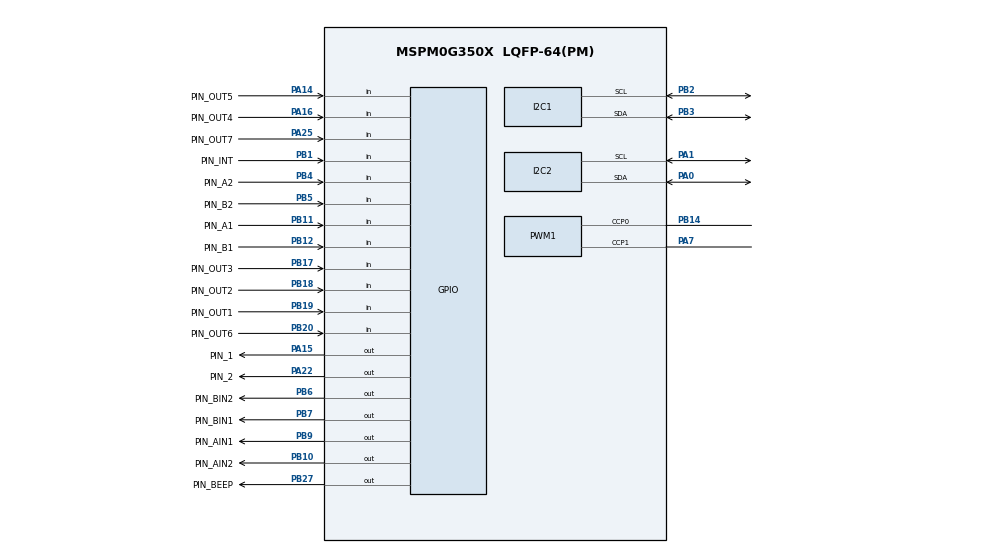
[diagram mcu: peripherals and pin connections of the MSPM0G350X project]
/**
 * @cliArgs --device "MSPM0G350X" --part "Default" --package "LQFP-64(PM)" --product "mspm0_sdk@2.05.00.05"
 * @versions {"tool":"1.24.0+4110"}
 */

/**
 * Import the modules used in this configuration.
 */
const GPIO   = scripting.addModule("/ti/driverlib/GPIO", {}, false);
const GPIO1  = GPIO.addInstance();
const GPIO2  = GPIO.addInstance();
const GPIO3  = GPIO.addInstance();
const GPIO4  = GPIO.addInstance();
const GPIO5  = GPIO.addInstance();
const I2C    = scripting.addModule("/ti/driverlib/I2C", {}, false);
const I2C1   = I2C.addInstance();
const I2C2   = I2C.addInstance();
const PWM    = scripting.addModule("/ti/driverlib/PWM", {}, false);
const PWM1   = PWM.addInstance();
const SYSCTL = scripting.addModule("/ti/driverlib/SYSCTL");
const TIMER  = scripting.addModule("/ti/driverlib/TIMER", {}, false);
const TIMER1 = TIMER.addInstance();

/**
 * Write custom configuration values to the imported modules.
 */
const divider7       = system.clockTree["PLL_PDIV"];
divider7.divideValue = 2;

const divider9       = system.clockTree["UDIV"];
divider9.divideValue = 2;

const multiplier2         = system.clockTree["PLL_QDIV"];
multiplier2.multiplyValue = 5;

const mux8       = system.clockTree["HSCLKMUX"];
mux8.inputSelect = "HSCLKMUX_SYSPLL2X";

GPIO1.$name                         = "GPIO_MOTOR";
GPIO1.associatedPins.create(4);
GPIO1.associatedPins[0].$name       = "PIN_AIN1";
GPIO1.associatedPins[0].pin.$assign = "PB9";
GPIO1.associatedPins[1].$name       = "PIN_AIN2";
GPIO1.associatedPins[1].pin.$assign = "PB10";
GPIO1.associatedPins[2].$name       = "PIN_BIN1";
GPIO1.associatedPins[2].pin.$assign = "PB7";
GPIO1.associatedPins[3].$name       = "PIN_BIN2";
GPIO1.associatedPins[3].pin.$assign = "PB6";

const Board = scripting.addModule("/ti/driverlib/Board", {}, false);

GPIO2.$name                               = "GPIO_ENCODER";
GPIO2.associatedPins.create(4);
GPIO2.associatedPins[0].$name             = "PIN_A1";
GPIO2.associatedPins[0].direction         = "INPUT";
GPIO2.associatedPins[0].interruptEn       = true;
GPIO2.associatedPins[0].interruptPriority = "1";
GPIO2.associatedPins[0].polarity          = "RISE_FALL";
GPIO2.associatedPins[0].pin.$assign       = "PB11";
GPIO2.associatedPins[1].$name             = "PIN_A2";
GPIO2.associatedPins[1].direction         = "INPUT";
GPIO2.associatedPins[1].interruptEn       = true;
GPIO2.associatedPins[1].interruptPriority = "1";
GPIO2.associatedPins[1].polarity          = "RISE_FALL";
GPIO2.associatedPins[1].pin.$assign       = "PB4";
GPIO2.associatedPins[2].$name             = "PIN_B1";
GPIO2.associatedPins[2].direction         = "INPUT";
GPIO2.associatedPins[2].interruptEn       = true;
GPIO2.associatedPins[2].interruptPriority = "1";
GPIO2.associatedPins[2].polarity          = "RISE_FALL";
GPIO2.associatedPins[2].pin.$assign       = "PB12";
GPIO2.associatedPins[3].$name             = "PIN_B2";
GPIO2.associatedPins[3].direction         = "INPUT";
GPIO2.associatedPins[3].interruptEn       = true;
GPIO2.associatedPins[3].interruptPriority = "1";
GPIO2.associatedPins[3].polarity          = "RISE_FALL";
GPIO2.associatedPins[3].pin.$assign       = "PB5";

GPIO3.$name                               = "GPIO_MPU6050";
GPIO3.associatedPins[0].$name             = "PIN_INT";
GPIO3.associatedPins[0].direction         = "INPUT";
GPIO3.associatedPins[0].internalResistor  = "PULL_UP";
GPIO3.associatedPins[0].interruptEn       = true;
GPIO3.associatedPins[0].interruptPriority = "1";
GPIO3.associatedPins[0].polarity          = "FALL";
GPIO3.associatedPins[0].pin.$assign       = "PB1";

GPIO4.$name                         = "GPIO_TRM";
GPIO4.associatedPins.create(7);
GPIO4.associatedPins[0].$name       = "PIN_OUT1";
GPIO4.associatedPins[0].direction   = "INPUT";
GPIO4.associatedPins[0].pin.$assign = "PB19";
GPIO4.associatedPins[1].$name       = "PIN_OUT2";
GPIO4.associatedPins[1].direction   = "INPUT";
GPIO4.associatedPins[1].pin.$assign = "PB18";
GPIO4.associatedPins[2].$name       = "PIN_OUT3";
GPIO4.associatedPins[2].direction   = "INPUT";
GPIO4.associatedPins[2].pin.$assign = "PB17";
GPIO4.associatedPins[3].$name       = "PIN_OUT4";
GPIO4.associatedPins[3].direction   = "INPUT";
GPIO4.associatedPins[3].pin.$assign = "PA16";
GPIO4.associatedPins[4].$name       = "PIN_OUT5";
GPIO4.associatedPins[4].direction   = "INPUT";
GPIO4.associatedPins[4].pin.$assign = "PA14";
GPIO4.associatedPins[5].$name       = "PIN_OUT6";
GPIO4.associatedPins[5].direction   = "INPUT";
GPIO4.associatedPins[5].pin.$assign = "PB20";
GPIO4.associatedPins[6].$name       = "PIN_OUT7";
GPIO4.associatedPins[6].direction   = "INPUT";
GPIO4.associatedPins[6].pin.$assign = "PA25";

GPIO5.$name                         = "GPIO_LED";
GPIO5.associatedPins.create(3);
GPIO5.associatedPins[0].$name       = "PIN_1";
GPIO5.associatedPins[0].pin.$assign = "PA15";
GPIO5.associatedPins[1].$name       = "PIN_2";
GPIO5.associatedPins[1].pin.$assign = "PA22";
GPIO5.associatedPins[2].$name       = "PIN_BEEP";
GPIO5.associatedPins[2].pin.$assign = "PB27";

I2C1.$name                             = "I2C_MPU6050";
I2C1.basicEnableController             = true;
I2C1.basicControllerStandardBusSpeed   = "Fast";
I2C1.peripheral.$assign                = "I2C1";
I2C1.peripheral.sdaPin.$assign         = "PB3";
I2C1.peripheral.sclPin.$assign         = "PB2";
I2C1.sdaPinConfig.$name                = "ti_driverlib_gpio_GPIOPinGeneric2";
I2C1.sdaPinConfig.hideOutputInversion  = scripting.forceWrite(false);
I2C1.sdaPinConfig.onlyInternalResistor = scripting.forceWrite(false);
I2C1.sdaPinConfig.passedPeripheralType = scripting.forceWrite("Digital");
I2C1.sclPinConfig.$name                = "ti_driverlib_gpio_GPIOPinGeneric3";
I2C1.sclPinConfig.hideOutputInversion  = scripting.forceWrite(false);
I2C1.sclPinConfig.onlyInternalResistor = scripting.forceWrite(false);
I2C1.sclPinConfig.passedPeripheralType = scripting.forceWrite("Digital");

I2C2.$name                             = "I2C_OLED";
I2C2.basicEnableController             = true;
I2C2.basicControllerStandardBusSpeed   = "Fast";
I2C2.peripheral.$assign                = "I2C0";
I2C2.peripheral.sdaPin.$assign         = "PA0";
I2C2.peripheral.sclPin.$assign         = "PA1";
I2C2.sdaPinConfig.$name                = "ti_driverlib_gpio_GPIOPinGeneric4";
I2C2.sdaPinConfig.hideOutputInversion  = scripting.forceWrite(false);
I2C2.sdaPinConfig.onlyInternalResistor = scripting.forceWrite(false);
I2C2.sdaPinConfig.passedPeripheralType = scripting.forceWrite("Digital");
I2C2.sclPinConfig.$name                = "ti_driverlib_gpio_GPIOPinGeneric5";
I2C2.sclPinConfig.hideOutputInversion  = scripting.forceWrite(false);
I2C2.sclPinConfig.onlyInternalResistor = scripting.forceWrite(false);
I2C2.sclPinConfig.passedPeripheralType = scripting.forceWrite("Digital");

PWM1.$name                              = "PWM_MOTOR";
PWM1.timerCount                         = 8000;
PWM1.peripheral.$assign                 = "TIMA0";
PWM1.peripheral.ccp0Pin.$assign         = "PB14";
PWM1.peripheral.ccp1Pin.$assign         = "PA7";
PWM1.PWM_CHANNEL_0.$name                = "ti_driverlib_pwm_PWMTimerCC0";
PWM1.PWM_CHANNEL_1.$name                = "ti_driverlib_pwm_PWMTimerCC1";
PWM1.ccp0PinConfig.$name                = "ti_driverlib_gpio_GPIOPinGeneric0";
PWM1.ccp0PinConfig.direction            = scripting.forceWrite("OUTPUT");
PWM1.ccp0PinConfig.hideOutputInversion  = scripting.forceWrite(false);
PWM1.ccp0PinConfig.onlyInternalResistor = scripting.forceWrite(false);
PWM1.ccp0PinConfig.passedPeripheralType = scripting.forceWrite("Digital");
PWM1.ccp1PinConfig.$name                = "ti_driverlib_gpio_GPIOPinGeneric1";
PWM1.ccp1PinConfig.direction            = scripting.forceWrite("OUTPUT");
PWM1.ccp1PinConfig.hideOutputInversion  = scripting.forceWrite(false);
PWM1.ccp1PinConfig.onlyInternalResistor = scripting.forceWrite(false);
PWM1.ccp1PinConfig.passedPeripheralType = scripting.forceWrite("Digital");

SYSCTL.forceDefaultClkConfig = true;
SYSCTL.clockTreeEn           = true;
scripting.suppress("For best practices when the CPUCLK is running at 32MHz and above, clear the flash status bit using DL_FlashCTL_executeClearStatus\\(\\) before executing any flash operation\\. Otherwise there may be false positives\\.", SYSCTL);

TIMER1.$name              = "TIMER_CALC";
TIMER1.timerPeriod        = "100 ms";
TIMER1.timerMode          = "PERIODIC";
TIMER1.timerClkPrescale   = 256;
TIMER1.interrupts         = ["ZERO"];
TIMER1.interruptPriority  = "1";
TIMER1.peripheral.$assign = "TIMA1";

/**
 * Pinmux solution for unlocked pins/peripherals. This ensures that minor changes to the automatic solver in a future
 * version of the tool will not impact the pinmux you originally saw.  These lines can be completely deleted in order to
 * re-solve from scratch.
 */
Board.peripheral.$suggestSolution          = "DEBUGSS";
Board.peripheral.swclkPin.$suggestSolution = "PA20";
Board.peripheral.swdioPin.$suggestSolution = "PA19";
